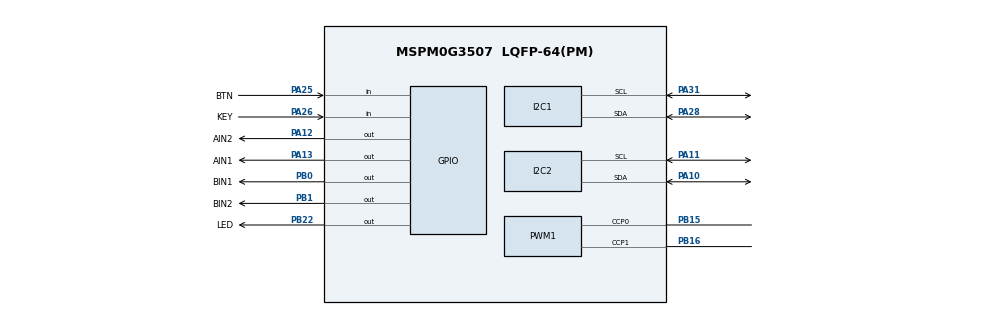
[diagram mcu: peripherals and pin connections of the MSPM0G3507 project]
/**
 * MSPM0G3507 小车直线 PID 测试
 *
 * I2C0 OLED:   PA28=SDA, PA31=SCL (0x3C)
 * I2C1 MPU:    PA10=SDA, PA11=SCL (0x68)
 * PWM Motor:   TIMG8, PB15=C0(左), PB16=C1(右)
 * LED:         PB22
 * CAL 按键:    PA26 (对地, yaw校零)
 * START 按键:  PA25 (对地, 启动/停止)
 * TB6612 方向: PB0=AIN1, PB1=AIN2, PB4=BIN1, PB5=BIN2 (⚠️ 按实际修改)
 */
//@cliArgs --device "MSPM0G350X" --package "LQFP-64(PM)" --part "Default"
//@v2CliArgs --device "MSPM0G3507" --package "LQFP-64(PM)"

const GPIO   = scripting.addModule("/ti/driverlib/GPIO", {}, false);
const GPIO1  = GPIO.addInstance();
const GPIO2  = GPIO.addInstance();
const GPIO3  = GPIO.addInstance();
const SYSCTL = scripting.addModule("/ti/driverlib/SYSCTL");
const I2C    = scripting.addModule("/ti/driverlib/I2C", {}, false);
const I2C1   = I2C.addInstance();
const I2C2   = I2C.addInstance();
const PWM    = scripting.addModule("/ti/driverlib/PWM", {}, false);
const PWM1   = PWM.addInstance();
const Board  = scripting.addModule("/ti/driverlib/Board", {}, false);

GPIO1.$name                         = "GPIO";
GPIO1.associatedPins[0].$name       = "LED";
GPIO1.associatedPins[0].pin.$assign = "PB22";

GPIO2.$name                         = "CAL";
GPIO2.associatedPins[0].$name       = "KEY";
GPIO2.associatedPins[0].pin.$assign = "PA26";
GPIO2.associatedPins[0].direction   = "INPUT";

GPIO3.$name                         = "START";
GPIO3.associatedPins[0].$name       = "BTN";
GPIO3.associatedPins[0].pin.$assign = "PA25";
GPIO3.associatedPins[0].direction   = "INPUT";

const GPIO4  = GPIO.addInstance();
GPIO4.$name                         = "DIR_L";
GPIO4.associatedPins.create(2);
GPIO4.associatedPins[0].$name       = "AIN1";
GPIO4.associatedPins[0].pin.$assign = "PA13";
GPIO4.associatedPins[1].$name       = "AIN2";
GPIO4.associatedPins[1].pin.$assign = "PA12";

const GPIO5  = GPIO.addInstance();
GPIO5.$name                         = "DIR_R";
GPIO5.associatedPins.create(2);
GPIO5.associatedPins[0].$name       = "BIN1";
GPIO5.associatedPins[0].pin.$assign = "PB0";
GPIO5.associatedPins[1].$name       = "BIN2";
GPIO5.associatedPins[1].pin.$assign = "PB1";

SYSCTL.forceDefaultClkConfig = true;

I2C1.$name                     = "I2C_OLED";
I2C1.peripheral.sdaPin.$assign = "PA28";
I2C1.peripheral.sclPin.$assign = "PA31";
I2C1.basicEnableController     = true;
I2C1.basicControllerBusSpeed   = 400000;
I2C1.advControllerTXFIFOTRIG   = "BYTES_1";
I2C1.sdaPinConfig.$name        = "ti_driverlib_gpio_GPIOPinGeneric0";
I2C1.sclPinConfig.$name        = "ti_driverlib_gpio_GPIOPinGeneric1";

I2C2.$name                     = "I2C_MPU";
I2C2.peripheral.sdaPin.$assign = "PA10";
I2C2.peripheral.sclPin.$assign = "PA11";
I2C2.basicEnableController     = true;
I2C2.basicControllerBusSpeed   = 400000;
I2C2.advControllerTXFIFOTRIG   = "BYTES_7";
I2C2.advControllerRXFIFOTRIG   = "BYTES_8";
I2C2.sdaPinConfig.$name        = "ti_driverlib_gpio_GPIOPinGeneric2";
I2C2.sclPinConfig.$name        = "ti_driverlib_gpio_GPIOPinGeneric3";

PWM1.$name                              = "MOTOR_PWM";
PWM1.timerStartTimer                    = true;
PWM1.timerCount                         = 2133;
PWM1.clockPrescale                      = 1;
PWM1.peripheral.ccp0Pin.$assign         = "PB15";
PWM1.peripheral.ccp1Pin.$assign         = "PB16";
PWM1.PWM_CHANNEL_0.$name                = "ti_driverlib_pwm_PWMTimerCC0";
PWM1.PWM_CHANNEL_1.$name                = "ti_driverlib_pwm_PWMTimerCC1";

Board.peripheral.$suggestSolution          = "DEBUGSS";
Board.peripheral.swclkPin.$suggestSolution = "PA20";
Board.peripheral.swdioPin.$suggestSolution = "PA19";
I2C1.peripheral.$suggestSolution           = "I2C0";
I2C2.peripheral.$suggestSolution           = "I2C1";
PWM1.peripheral.$suggestSolution           = "TIMG8";
